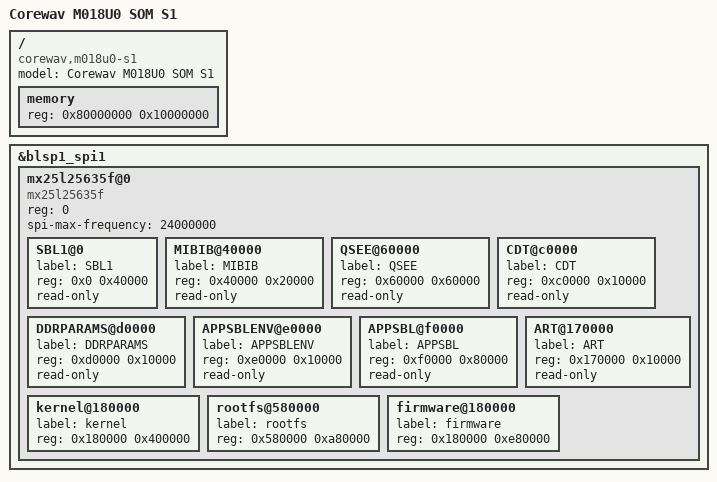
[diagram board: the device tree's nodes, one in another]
// SPDX-License-Identifier: GPL-2.0-or-later

#include "qcom-ipq4018-m018u0.dtsi"

/ {
	model = "Corewav M018U0 SOM S1";
	compatible = "corewav,m018u0-s1";

	memory {
		device_type = "memory";
		reg = <0x80000000 0x10000000>;
	};
};

&blsp1_spi1 {
	mx25l25635f@0 {
		compatible = "mx25l25635f", "jedec,spi-nor";
		#address-cells = <1>;
		#size-cells = <1>;
		reg = <0>;
		spi-max-frequency = <24000000>;

		SBL1@0 {
			label = "SBL1";
			reg = <0x0 0x40000>;
			read-only;
		};

		MIBIB@40000 {
			label = "MIBIB";
			reg = <0x40000 0x20000>;
			read-only;
		};

		QSEE@60000 {
			label = "QSEE";
			reg = <0x60000 0x60000>;
			read-only;
		};

		CDT@c0000 {
			label = "CDT";
			reg = <0xc0000 0x10000>;
			read-only;
		};

		DDRPARAMS@d0000 {
			label = "DDRPARAMS";
			reg = <0xd0000 0x10000>;
			read-only;
		};

		APPSBLENV@e0000 {
			label = "APPSBLENV";
			reg = <0xe0000 0x10000>;
			read-only;
		};

		APPSBL@f0000 {
			label = "APPSBL";
			reg = <0xf0000 0x80000>;
			read-only;
		};

		ART@170000 {
			label = "ART";
			reg = <0x170000 0x10000>;
			read-only;
		};

		kernel@180000 {
			label = "kernel";
			reg = <0x180000 0x400000>;
		};

		rootfs@580000 {
			label = "rootfs";
			reg = <0x580000 0xa80000>;
		};

		firmware@180000 {
			label = "firmware";
			reg = <0x180000 0xe80000>;
		};
	};
};
